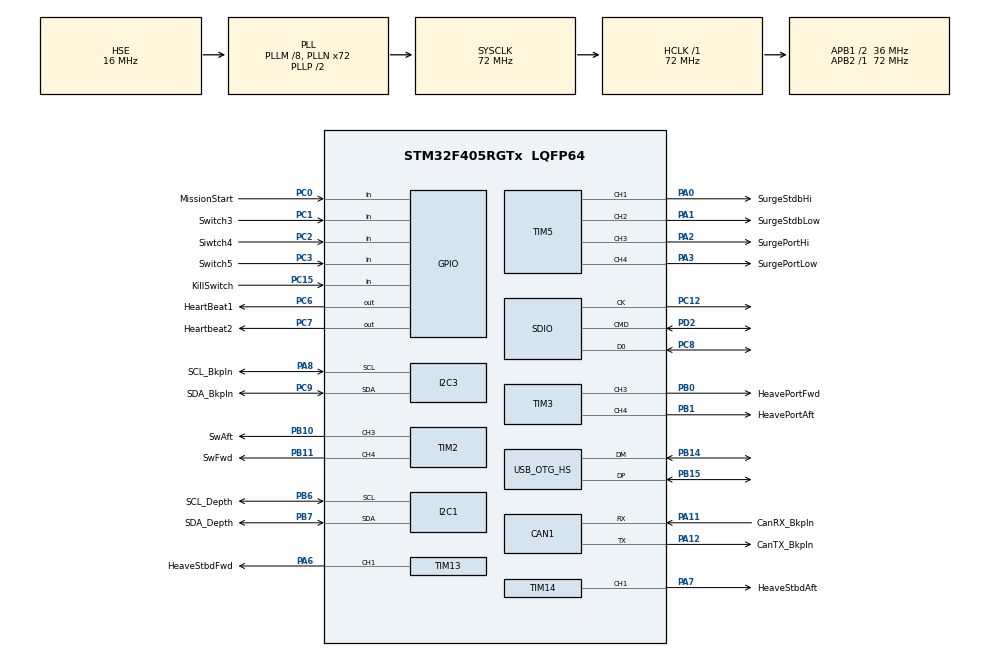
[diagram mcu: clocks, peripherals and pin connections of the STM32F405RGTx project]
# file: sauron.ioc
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CAN1.CalculateTimeBit=1333
CAN1.CalculateTimeQuantum=444.44444444444446
FREERTOS.Tasks01=defaultTask,0,128,StartDefaultTask,Default,NULL
Mcu.Family=STM32F4
Mcu.Name=STM32F405RGTx
Mcu.Package=LQFP64
NVIC.OTG_HS_IRQn=true\:5\:0\:false\:false\:true\:true\:true
NVIC.PriorityGroup=NVIC_PRIORITYGROUP_4
NVIC.TIM1_UP_TIM10_IRQn=true\:0\:0\:false\:false\:true\:false\:true
NVIC.TimeBase=TIM1_UP_TIM10_IRQn
NVIC.TimeBaseIP=TIM1
PA0-WKUP.GPIO_Label=SurgeStdbHi
PA0-WKUP.Signal=S_TIM5_CH1
PA1.GPIO_Label=SurgeStdbLow
PA1.Signal=S_TIM5_CH2
PA11.GPIO_Label=CanRX_Bkpln
PA11.Mode=Master
PA11.Signal=CAN1_RX
PA12.GPIO_Label=CanTX_Bkpln
PA12.Mode=Master
PA12.Signal=CAN1_TX
PA13.Mode=JTAG_5_pins
PA13.Signal=SYS_JTMS-SWDIO
PA14.Mode=JTAG_5_pins
PA14.Signal=SYS_JTCK-SWCLK
PA15.Mode=JTAG_5_pins
PA15.Signal=SYS_JTDI
PA2.GPIO_Label=SurgePortHi
PA2.Signal=S_TIM5_CH3
PA3.GPIO_Label=SurgePortLow
PA3.Signal=S_TIM5_CH4
PA6.GPIO_Label=HeaveStbdFwd
PA6.Signal=S_TIM13_CH1
PA7.GPIO_Label=HeaveStbdAft
PA7.Signal=S_TIM14_CH1
PA8.GPIO_Label=SCL_Bkpln
PA8.Mode=I2C
PA8.Signal=I2C3_SCL
PB0.GPIO_Label=HeavePortFwd
PB0.Signal=S_TIM3_CH3
PB1.GPIO_Label=HeavePortAft
PB1.Signal=S_TIM3_CH4
PB10.GPIO_Label=SwAft
PB10.Signal=S_TIM2_CH3
PB11.GPIO_Label=SwFwd
PB11.Signal=S_TIM2_CH4
PB14.GPIO_Mode=GPIO_MODE_AF_PP
PB14.Mode=Device_Only_FS
PB14.Signal=USB_OTG_HS_DM
PB15.Mode=Device_Only_FS
PB15.Signal=USB_OTG_HS_DP
PB3.Mode=JTAG_5_pins
PB3.Signal=SYS_JTDO-SWO
PB4.Mode=JTAG_5_pins
PB4.Signal=SYS_JTRST
PB6.GPIO_Label=SCL_Depth
PB6.Mode=I2C
PB6.Signal=I2C1_SCL
PB7.GPIO_Label=SDA_Depth
PB7.Mode=I2C
PB7.Signal=I2C1_SDA
PC0.GPIO_Label=MissionStart
PC0.Signal=GPIO_Input
PC1.GPIO_Label=Switch3
PC1.Signal=GPIO_Input
PC12.Mode=SD_1_bit
PC12.Signal=SDIO_CK
PC15-OSC32_OUT.GPIO_Label=KillSwitch
PC15-OSC32_OUT.Signal=GPIO_Input
PC2.GPIO_Label=Siwtch4
PC2.Signal=GPIO_Input
PC3.GPIO_Label=Switch5
PC3.Signal=GPIO_Input
PC6.GPIO_Label=HeartBeat1
PC6.Signal=GPIO_Output
PC7.GPIO_Label=Heartbeat2
PC7.Signal=GPIO_Output
PC8.Mode=SD_1_bit
PC8.Signal=SDIO_D0
PC9.GPIO_Label=SDA_Bkpln
PC9.Mode=I2C
PC9.Signal=I2C3_SDA
PD2.Mode=SD_1_bit
PD2.Signal=SDIO_CMD
PH0-OSC_IN.Mode=HSE-External-Oscillator
PH0-OSC_IN.Signal=RCC_OSC_IN
PH1-OSC_OUT.Mode=HSE-External-Oscillator
PH1-OSC_OUT.Signal=RCC_OSC_OUT
ProjectManager.HeapSize=0x200
ProjectManager.StackSize=0x400
ProjectManager.TargetToolchain=Makefile
RCC.48MHZClocksFreq_Value=48000000
RCC.AHBFreq_Value=72000000
RCC.APB1CLKDivider=RCC_HCLK_DIV2
RCC.APB1Freq_Value=36000000
RCC.APB1TimFreq_Value=72000000
RCC.APB2Freq_Value=72000000
RCC.APB2TimFreq_Value=72000000
RCC.CortexFreq_Value=72000000
RCC.HCLKFreq_Value=72000000
RCC.HSE_VALUE=16000000
RCC.HSI_VALUE=16000000
RCC.LSE_VALUE=32768
RCC.PLLM=8
RCC.PLLN=72
RCC.PLLQ=3
RCC.SYSCLKFreq_VALUE=72000000
RCC.SYSCLKSource=RCC_SYSCLKSOURCE_PLLCLK
RCC.VCOOutputFreq_Value=144000000
SH.S_TIM13_CH1.0=TIM13_CH1,PWM Generation1 CH1
SH.S_TIM14_CH1.0=TIM14_CH1,PWM Generation1 CH1
SH.S_TIM2_CH3.0=TIM2_CH3,PWM Generation3 CH3
SH.S_TIM2_CH4.0=TIM2_CH4,PWM Generation4 CH4
SH.S_TIM3_CH3.0=TIM3_CH3,PWM Generation3 CH3
SH.S_TIM3_CH4.0=TIM3_CH4,PWM Generation4 CH4
SH.S_TIM5_CH1.0=TIM5_CH1,PWM Generation1 CH1
SH.S_TIM5_CH2.0=TIM5_CH2,PWM Generation2 CH2
SH.S_TIM5_CH3.0=TIM5_CH3,PWM Generation3 CH3
SH.S_TIM5_CH4.0=TIM5_CH4,PWM Generation4 CH4
TIM13.Channel=TIM_CHANNEL_1
TIM14.Channel=TIM_CHANNEL_1
TIM2.Channel-PWM\ Generation3\ CH3=TIM_CHANNEL_3
TIM2.Channel-PWM\ Generation4\ CH4=TIM_CHANNEL_4
TIM3.Channel-PWM\ Generation3\ CH3=TIM_CHANNEL_3
TIM3.Channel-PWM\ Generation4\ CH4=TIM_CHANNEL_4
TIM5.Channel-PWM\ Generation1\ CH1=TIM_CHANNEL_1
TIM5.Channel-PWM\ Generation2\ CH2=TIM_CHANNEL_2
TIM5.Channel-PWM\ Generation3\ CH3=TIM_CHANNEL_3
TIM5.Channel-PWM\ Generation4\ CH4=TIM_CHANNEL_4
USB_DEVICE.CLASS_NAME_HS=CDC
USB_DEVICE.VirtualMode-CDC_HS=Cdc
USB_DEVICE.VirtualModeHS=Cdc_HS
USB_OTG_HS.VirtualMode-Device_Only_FS=Device_Only_FS
VP_FREERTOS_VS_ENABLE.Mode=Enabled
VP_SYS_VS_tim1.Mode=TIM1
VP_TIM13_VS_ClockSourceINT.Mode=Enable_Timer
VP_TIM14_VS_ClockSourceINT.Mode=Enable_Timer
VP_USB_DEVICE_VS_USB_DEVICE_CDC_HS.Mode=CDC_HS
board=sauron

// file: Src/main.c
/**
  ******************************************************************************
  * File Name          : main.c
  * Description        : Main program body
  ******************************************************************************
  * This notice applies to any and all portions of this file
  * that are not between comment pairs USER CODE BEGIN and
  * USER CODE END. Other portions of this file, whether
  * inserted by the user or by software development tools
  * are owned by their respective copyright owners.
  *
  * Copyright (c) 2018 STMicroelectronics International N.V.
  * All rights reserved.
  *
  * Redistribution and use in source and binary forms, with or without
  * modification, are permitted, provided that the following conditions are met:
  *
  * 1. Redistribution of source code must retain the above copyright notice,
  *    this list of conditions and the following disclaimer.
  * 2. Redistributions in binary form must reproduce the above copyright notice,
  *    this list of conditions and the following disclaimer in the documentation
  *    and/or other materials provided with the distribution.
  * 3. Neither the name of STMicroelectronics nor the names of other
  *    contributors to this software may be used to endorse or promote products
  *    derived from this software without specific written permission.
  * 4. This software, including modifications and/or derivative works of this
  *    software, must execute solely and exclusively on microcontroller or
  *    microprocessor devices manufactured by or for STMicroelectronics.
  * 5. Redistribution and use of this software other than as permitted under
  *    this license is void and will automatically terminate your rights under
  *    this license.
  *
  * THIS SOFTWARE IS PROVIDED BY STMICROELECTRONICS AND CONTRIBUTORS "AS IS"
  * AND ANY EXPRESS, IMPLIED OR STATUTORY WARRANTIES, INCLUDING, BUT NOT
  * LIMITED TO, THE IMPLIED WARRANTIES OF MERCHANTABILITY, FITNESS FOR A
  * PARTICULAR PURPOSE AND NON-INFRINGEMENT OF THIRD PARTY INTELLECTUAL PROPERTY
  * RIGHTS ARE DISCLAIMED TO THE FULLEST EXTENT PERMITTED BY LAW. IN NO EVENT
  * SHALL STMICROELECTRONICS OR CONTRIBUTORS BE LIABLE FOR ANY DIRECT, INDIRECT,
  * INCIDENTAL, SPECIAL, EXEMPLARY, OR CONSEQUENTIAL DAMAGES (INCLUDING, BUT NOT
  * LIMITED TO, PROCUREMENT OF SUBSTITUTE GOODS OR SERVICES; LOSS OF USE, DATA,
  * OR PROFITS; OR BUSINESS INTERRUPTION) HOWEVER CAUSED AND ON ANY THEORY OF
  * LIABILITY, WHETHER IN CONTRACT, STRICT LIABILITY, OR TORT (INCLUDING
  * NEGLIGENCE OR OTHERWISE) ARISING IN ANY WAY OUT OF THE USE OF THIS SOFTWARE,
  * EVEN IF ADVISED OF THE POSSIBILITY OF SUCH DAMAGE.
  *
  ******************************************************************************
  */
#include "main.h"
#include "stm32f4xx_hal.h"
#include "cmsis_os.h"
#include "usb_device.h"

/* USER CODE BEGIN Includes */
#include "riptideMain.h"
/* USER CODE END Includes */

CAN_HandleTypeDef hcan1;

I2C_HandleTypeDef hi2c1;
I2C_HandleTypeDef hi2c3;

SD_HandleTypeDef hsd;

TIM_HandleTypeDef htim2;
TIM_HandleTypeDef htim3;
TIM_HandleTypeDef htim5;
TIM_HandleTypeDef htim13;
TIM_HandleTypeDef htim14;

osThreadId defaultTaskHandle;

/* USER CODE BEGIN PV */
/* Private variables ---------------------------------------------------------*/

/* USER CODE END PV */

void SystemClock_Config(void);
static void MX_GPIO_Init(void);
static void MX_CAN1_Init(void);
static void MX_I2C1_Init(void);
static void MX_SDIO_SD_Init(void);
static void MX_TIM2_Init(void);
static void MX_TIM3_Init(void);
static void MX_TIM5_Init(void);
static void MX_TIM13_Init(void);
static void MX_TIM14_Init(void);
static void MX_I2C3_Init(void);
void StartDefaultTask(void const * argument);

void HAL_TIM_MspPostInit(TIM_HandleTypeDef *htim);

/* USER CODE BEGIN PFP */
/* Private function prototypes -----------------------------------------------*/

/* USER CODE END PFP */

int main(void)
{

  /* MCU Configuration----------------------------------------------------------*/

  /* Reset of all peripherals, Initializes the Flash interface and the Systick. */
  HAL_Init();

  /* Configure the system clock */
  SystemClock_Config();

  /* Initialize all configured peripherals */
  MX_GPIO_Init();
  MX_CAN1_Init();
  MX_I2C1_Init();
  MX_SDIO_SD_Init();
  MX_TIM2_Init();
  MX_TIM3_Init();
  MX_TIM5_Init();
  MX_TIM13_Init();
  MX_TIM14_Init();
  MX_I2C3_Init();

  /* USER CODE BEGIN 2 */
    riptideMain();
  /* USER CODE END 2 */

  /* Create the thread(s) */
  /* definition and creation of defaultTask */
  osThreadDef(defaultTask, StartDefaultTask, osPriorityNormal, 0, 128);
  defaultTaskHandle = osThreadCreate(osThread(defaultTask), NULL);

  /* Start scheduler */
  osKernelStart();

  /* We should never get here as control is now taken by the scheduler */

  /* Infinite loop */
  while (1)
  {

  }

}

/** System Clock Configuration
*/
void SystemClock_Config(void)
{

  RCC_OscInitTypeDef RCC_OscInitStruct;
  RCC_ClkInitTypeDef RCC_ClkInitStruct;

    /**Configure the main internal regulator output voltage
    */
  __HAL_RCC_PWR_CLK_ENABLE();

  __HAL_PWR_VOLTAGESCALING_CONFIG(PWR_REGULATOR_VOLTAGE_SCALE1);

    /**Initializes the CPU, AHB and APB busses clocks
    */
  RCC_OscInitStruct.OscillatorType = RCC_OSCILLATORTYPE_HSE;
  RCC_OscInitStruct.HSEState = RCC_HSE_ON;
  RCC_OscInitStruct.PLL.PLLState = RCC_PLL_ON;
  RCC_OscInitStruct.PLL.PLLSource = RCC_PLLSOURCE_HSE;
  RCC_OscInitStruct.PLL.PLLM = 8;
  RCC_OscInitStruct.PLL.PLLN = 72;
  RCC_OscInitStruct.PLL.PLLP = RCC_PLLP_DIV2;
  RCC_OscInitStruct.PLL.PLLQ = 3;
  if (HAL_RCC_OscConfig(&RCC_OscInitStruct) != HAL_OK)
  {
    _Error_Handler(__FILE__, __LINE__);
  }

    /**Initializes the CPU, AHB and APB busses clocks
    */
  RCC_ClkInitStruct.ClockType = RCC_CLOCKTYPE_HCLK|RCC_CLOCKTYPE_SYSCLK
                              |RCC_CLOCKTYPE_PCLK1|RCC_CLOCKTYPE_PCLK2;
  RCC_ClkInitStruct.SYSCLKSource = RCC_SYSCLKSOURCE_PLLCLK;
  RCC_ClkInitStruct.AHBCLKDivider = RCC_SYSCLK_DIV1;
  RCC_ClkInitStruct.APB1CLKDivider = RCC_HCLK_DIV2;
  RCC_ClkInitStruct.APB2CLKDivider = RCC_HCLK_DIV1;

  if (HAL_RCC_ClockConfig(&RCC_ClkInitStruct, FLASH_LATENCY_2) != HAL_OK)
  {
    _Error_Handler(__FILE__, __LINE__);
  }

    /**Configure the Systick interrupt time
    */
  HAL_SYSTICK_Config(HAL_RCC_GetHCLKFreq()/1000);

    /**Configure the Systick
    */
  HAL_SYSTICK_CLKSourceConfig(SYSTICK_CLKSOURCE_HCLK);

  /* SysTick_IRQn interrupt configuration */
  HAL_NVIC_SetPriority(SysTick_IRQn, 15, 0);
}

/* CAN1 init function */
static void MX_CAN1_Init(void)
{

  hcan1.Instance = CAN1;
  hcan1.Init.Prescaler = 16;
  hcan1.Init.Mode = CAN_MODE_NORMAL;
  hcan1.Init.SJW = CAN_SJW_1TQ;
  hcan1.Init.BS1 = CAN_BS1_1TQ;
  hcan1.Init.BS2 = CAN_BS2_1TQ;
  hcan1.Init.TTCM = DISABLE;
  hcan1.Init.ABOM = DISABLE;
  hcan1.Init.AWUM = DISABLE;
  hcan1.Init.NART = DISABLE;
  hcan1.Init.RFLM = DISABLE;
  hcan1.Init.TXFP = DISABLE;
  if (HAL_CAN_Init(&hcan1) != HAL_OK)
  {
    _Error_Handler(__FILE__, __LINE__);
  }

}

/* I2C1 init function */
static void MX_I2C1_Init(void)
{

  hi2c1.Instance = I2C1;
  hi2c1.Init.ClockSpeed = 100000;
  hi2c1.Init.DutyCycle = I2C_DUTYCYCLE_2;
  hi2c1.Init.OwnAddress1 = 0;
  hi2c1.Init.AddressingMode = I2C_ADDRESSINGMODE_7BIT;
  hi2c1.Init.DualAddressMode = I2C_DUALADDRESS_DISABLE;
  hi2c1.Init.OwnAddress2 = 0;
  hi2c1.Init.GeneralCallMode = I2C_GENERALCALL_DISABLE;
  hi2c1.Init.NoStretchMode = I2C_NOSTRETCH_DISABLE;
  if (HAL_I2C_Init(&hi2c1) != HAL_OK)
  {
    _Error_Handler(__FILE__, __LINE__);
  }

}

/* I2C3 init function */
static void MX_I2C3_Init(void)
{

  hi2c3.Instance = I2C3;
  hi2c3.Init.ClockSpeed = 100000;
  hi2c3.Init.DutyCycle = I2C_DUTYCYCLE_2;
  hi2c3.Init.OwnAddress1 = 0;
  hi2c3.Init.AddressingMode = I2C_ADDRESSINGMODE_7BIT;
  hi2c3.Init.DualAddressMode = I2C_DUALADDRESS_DISABLE;
  hi2c3.Init.OwnAddress2 = 0;
  hi2c3.Init.GeneralCallMode = I2C_GENERALCALL_DISABLE;
  hi2c3.Init.NoStretchMode = I2C_NOSTRETCH_DISABLE;
  if (HAL_I2C_Init(&hi2c3) != HAL_OK)
  {
    _Error_Handler(__FILE__, __LINE__);
  }

}

/* SDIO init function */
static void MX_SDIO_SD_Init(void)
{

  hsd.Instance = SDIO;
  hsd.Init.ClockEdge = SDIO_CLOCK_EDGE_RISING;
  hsd.Init.ClockBypass = SDIO_CLOCK_BYPASS_DISABLE;
  hsd.Init.ClockPowerSave = SDIO_CLOCK_POWER_SAVE_DISABLE;
  hsd.Init.BusWide = SDIO_BUS_WIDE_1B;
  hsd.Init.HardwareFlowControl = SDIO_HARDWARE_FLOW_CONTROL_DISABLE;
  hsd.Init.ClockDiv = 0;
  if (HAL_SD_Init(&hsd) != HAL_OK)
  {
    _Error_Handler(__FILE__, __LINE__);
  }

}

/* TIM2 init function */
static void MX_TIM2_Init(void)
{

  TIM_MasterConfigTypeDef sMasterConfig;
  TIM_OC_InitTypeDef sConfigOC;

  htim2.Instance = TIM2;
  htim2.Init.Prescaler = 0;
  htim2.Init.CounterMode = TIM_COUNTERMODE_UP;
  htim2.Init.Period = 0;
  htim2.Init.ClockDivision = TIM_CLOCKDIVISION_DIV1;
  if (HAL_TIM_PWM_Init(&htim2) != HAL_OK)
  {
    _Error_Handler(__FILE__, __LINE__);
  }

  sMasterConfig.MasterOutputTrigger = TIM_TRGO_RESET;
  sMasterConfig.MasterSlaveMode = TIM_MASTERSLAVEMODE_DISABLE;
  if (HAL_TIMEx_MasterConfigSynchronization(&htim2, &sMasterConfig) != HAL_OK)
  {
    _Error_Handler(__FILE__, __LINE__);
  }

  sConfigOC.OCMode = TIM_OCMODE_PWM1;
  sConfigOC.Pulse = 0;
  sConfigOC.OCPolarity = TIM_OCPOLARITY_HIGH;
  sConfigOC.OCFastMode = TIM_OCFAST_DISABLE;
  if (HAL_TIM_PWM_ConfigChannel(&htim2, &sConfigOC, TIM_CHANNEL_3) != HAL_OK)
  {
    _Error_Handler(__FILE__, __LINE__);
  }

  if (HAL_TIM_PWM_ConfigChannel(&htim2, &sConfigOC, TIM_CHANNEL_4) != HAL_OK)
  {
    _Error_Handler(__FILE__, __LINE__);
  }

  HAL_TIM_MspPostInit(&htim2);

}

/* TIM3 init function */
static void MX_TIM3_Init(void)
{

  TIM_MasterConfigTypeDef sMasterConfig;
  TIM_OC_InitTypeDef sConfigOC;

  htim3.Instance = TIM3;
  htim3.Init.Prescaler = 0;
  htim3.Init.CounterMode = TIM_COUNTERMODE_UP;
  htim3.Init.Period = 0;
  htim3.Init.ClockDivision = TIM_CLOCKDIVISION_DIV1;
  if (HAL_TIM_PWM_Init(&htim3) != HAL_OK)
  {
    _Error_Handler(__FILE__, __LINE__);
  }

  sMasterConfig.MasterOutputTrigger = TIM_TRGO_RESET;
  sMasterConfig.MasterSlaveMode = TIM_MASTERSLAVEMODE_DISABLE;
  if (HAL_TIMEx_MasterConfigSynchronization(&htim3, &sMasterConfig) != HAL_OK)
  {
    _Error_Handler(__FILE__, __LINE__);
  }

  sConfigOC.OCMode = TIM_OCMODE_PWM1;
  sConfigOC.Pulse = 0;
  sConfigOC.OCPolarity = TIM_OCPOLARITY_HIGH;
  sConfigOC.OCFastMode = TIM_OCFAST_DISABLE;
  if (HAL_TIM_PWM_ConfigChannel(&htim3, &sConfigOC, TIM_CHANNEL_3) != HAL_OK)
  {
    _Error_Handler(__FILE__, __LINE__);
  }

  if (HAL_TIM_PWM_ConfigChannel(&htim3, &sConfigOC, TIM_CHANNEL_4) != HAL_OK)
  {
    _Error_Handler(__FILE__, __LINE__);
  }

  HAL_TIM_MspPostInit(&htim3);

}

/* TIM5 init function */
static void MX_TIM5_Init(void)
{

  TIM_MasterConfigTypeDef sMasterConfig;
  TIM_OC_InitTypeDef sConfigOC;

  htim5.Instance = TIM5;
  htim5.Init.Prescaler = 0;
  htim5.Init.CounterMode = TIM_COUNTERMODE_UP;
  htim5.Init.Period = 0;
  htim5.Init.ClockDivision = TIM_CLOCKDIVISION_DIV1;
  if (HAL_TIM_PWM_Init(&htim5) != HAL_OK)
  {
    _Error_Handler(__FILE__, __LINE__);
  }

  sMasterConfig.MasterOutputTrigger = TIM_TRGO_RESET;
  sMasterConfig.MasterSlaveMode = TIM_MASTERSLAVEMODE_DISABLE;
  if (HAL_TIMEx_MasterConfigSynchronization(&htim5, &sMasterConfig) != HAL_OK)
  {
    _Error_Handler(__FILE__, __LINE__);
  }

  sConfigOC.OCMode = TIM_OCMODE_PWM1;
  sConfigOC.Pulse = 0;
  sConfigOC.OCPolarity = TIM_OCPOLARITY_HIGH;
  sConfigOC.OCFastMode = TIM_OCFAST_DISABLE;
  if (HAL_TIM_PWM_ConfigChannel(&htim5, &sConfigOC, TIM_CHANNEL_1) != HAL_OK)
  {
    _Error_Handler(__FILE__, __LINE__);
  }

  if (HAL_TIM_PWM_ConfigChannel(&htim5, &sConfigOC, TIM_CHANNEL_2) != HAL_OK)
  {
    _Error_Handler(__FILE__, __LINE__);
  }

  if (HAL_TIM_PWM_ConfigChannel(&htim5, &sConfigOC, TIM_CHANNEL_3) != HAL_OK)
  {
    _Error_Handler(__FILE__, __LINE__);
  }

  if (HAL_TIM_PWM_ConfigChannel(&htim5, &sConfigOC, TIM_CHANNEL_4) != HAL_OK)
  {
    _Error_Handler(__FILE__, __LINE__);
  }

  HAL_TIM_MspPostInit(&htim5);

}

/* TIM13 init function */
static void MX_TIM13_Init(void)
{

  TIM_OC_InitTypeDef sConfigOC;

  htim13.Instance = TIM13;
  htim13.Init.Prescaler = 0;
  htim13.Init.CounterMode = TIM_COUNTERMODE_UP;
  htim13.Init.Period = 0;
  htim13.Init.ClockDivision = TIM_CLOCKDIVISION_DIV1;
  if (HAL_TIM_Base_Init(&htim13) != HAL_OK)
  {
    _Error_Handler(__FILE__, __LINE__);
  }

  if (HAL_TIM_PWM_Init(&htim13) != HAL_OK)
  {
    _Error_Handler(__FILE__, __LINE__);
  }

  sConfigOC.OCMode = TIM_OCMODE_PWM1;
  sConfigOC.Pulse = 0;
  sConfigOC.OCPolarity = TIM_OCPOLARITY_HIGH;
  sConfigOC.OCFastMode = TIM_OCFAST_DISABLE;
  if (HAL_TIM_PWM_ConfigChannel(&htim13, &sConfigOC, TIM_CHANNEL_1) != HAL_OK)
  {
    _Error_Handler(__FILE__, __LINE__);
  }

  HAL_TIM_MspPostInit(&htim13);

}

/* TIM14 init function */
static void MX_TIM14_Init(void)
{

  TIM_OC_InitTypeDef sConfigOC;

  htim14.Instance = TIM14;
  htim14.Init.Prescaler = 0;
  htim14.Init.CounterMode = TIM_COUNTERMODE_UP;
  htim14.Init.Period = 0;
  htim14.Init.ClockDivision = TIM_CLOCKDIVISION_DIV1;
  if (HAL_TIM_Base_Init(&htim14) != HAL_OK)
  {
    _Error_Handler(__FILE__, __LINE__);
  }

  if (HAL_TIM_PWM_Init(&htim14) != HAL_OK)
  {
    _Error_Handler(__FILE__, __LINE__);
  }

  sConfigOC.OCMode = TIM_OCMODE_PWM1;
  sConfigOC.Pulse = 0;
  sConfigOC.OCPolarity = TIM_OCPOLARITY_HIGH;
  sConfigOC.OCFastMode = TIM_OCFAST_DISABLE;
  if (HAL_TIM_PWM_ConfigChannel(&htim14, &sConfigOC, TIM_CHANNEL_1) != HAL_OK)
  {
    _Error_Handler(__FILE__, __LINE__);
  }

  HAL_TIM_MspPostInit(&htim14);

}

/** Configure pins as
        * Analog
        * Input
        * Output
        * EVENT_OUT
        * EXTI
*/
static void MX_GPIO_Init(void)
{

  GPIO_InitTypeDef GPIO_InitStruct;

  /* GPIO Ports Clock Enable */
  __HAL_RCC_GPIOC_CLK_ENABLE();
  __HAL_RCC_GPIOH_CLK_ENABLE();
  __HAL_RCC_GPIOA_CLK_ENABLE();
  __HAL_RCC_GPIOB_CLK_ENABLE();
  __HAL_RCC_GPIOD_CLK_ENABLE();

  /*Configure GPIO pin Output Level */
  HAL_GPIO_WritePin(GPIOC, HeartBeat1_Pin|Heartbeat2_Pin, GPIO_PIN_RESET);

  /*Configure GPIO pins : KillSwitch_Pin MissionStart_Pin Switch3_Pin Siwtch4_Pin
                           Switch5_Pin */
  GPIO_InitStruct.Pin = KillSwitch_Pin|MissionStart_Pin|Switch3_Pin|Siwtch4_Pin
                          |Switch5_Pin;
  GPIO_InitStruct.Mode = GPIO_MODE_INPUT;
  GPIO_InitStruct.Pull = GPIO_NOPULL;
  HAL_GPIO_Init(GPIOC, &GPIO_InitStruct);

  /*Configure GPIO pins : HeartBeat1_Pin Heartbeat2_Pin */
  GPIO_InitStruct.Pin = HeartBeat1_Pin|Heartbeat2_Pin;
  GPIO_InitStruct.Mode = GPIO_MODE_OUTPUT_PP;
  GPIO_InitStruct.Pull = GPIO_NOPULL;
  GPIO_InitStruct.Speed = GPIO_SPEED_FREQ_LOW;
  HAL_GPIO_Init(GPIOC, &GPIO_InitStruct);

}

/* StartDefaultTask function */
void StartDefaultTask(void const * argument)
{
  /* init code for USB_DEVICE */
  MX_USB_DEVICE_Init();

  for(;;)
  {
    osDelay(1);
  }
}

void HAL_TIM_PeriodElapsedCallback(TIM_HandleTypeDef *htim)
{
  if (htim->Instance == TIM1) {
    HAL_IncTick();
  }
}

void _Error_Handler(char * file, int line)
{
  while(1)
  {
  }
}

/************************ (C) COPYRIGHT STMicroelectronics *****END OF FILE****/
